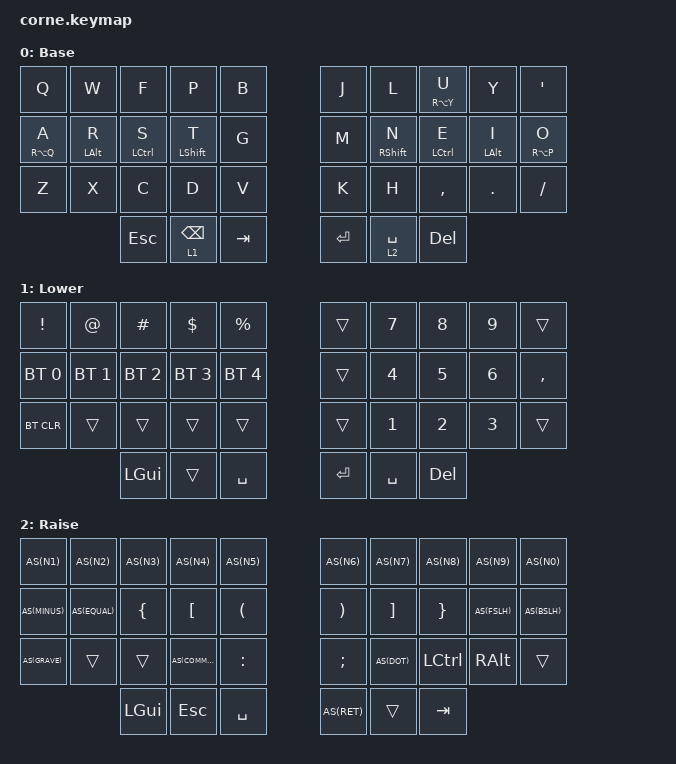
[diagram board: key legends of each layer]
/*
 * Copyright (c) 2020 The ZMK Contributors
 *
 * SPDX-License-Identifier: MIT
 */

#include <behaviors.dtsi>
#include <dt-bindings/zmk/keys.h>
#include <dt-bindings/zmk/bt.h>
#include <behaviors/unicode.dtsi>


#define AS(keycode) &as LS(keycode) keycode

/ {
    chosen {
        zmk,physical-layout = &foostan_corne_5col_layout;
    };

    behaviors {
        hml: home_row_mod_left {
            compatible = "zmk,behavior-hold-tap";
            #binding-cells = <2>;
            flavor = "balanced";
            require-prior-idle-ms = <150>;
            tapping-term-ms = <280>;
            quick-tap-ms = <175>;
            bindings = <&kp>, <&kp>;
            hold-trigger-key-positions = < 5 6 7 8 9 15 16 17 18 19 25 26 27 28 29 30 31 32 33 34 35>; // List of keys on the right side of the keyboard
            hold-trigger-on-release;
        };
        hmr: home_row_mod_right {
            compatible = "zmk,behavior-hold-tap";
            #binding-cells = <2>;
            flavor = "balanced";
            require-prior-idle-ms = <150>;
            tapping-term-ms = <280>;
            quick-tap-ms = <175>;
            bindings = <&kp>, <&kp>;
            hold-trigger-key-positions = < 0 1 2 3 4 10 11 12 13 14 20 21 22 23 24 30 31 32 33 34 35 >; // List of keys on the left side of the keyboard
            hold-trigger-on-release;
        };
        as: auto_shift {
            compatible = "zmk,behavior-hold-tap";
            #binding-cells = <2>;
            tapping_term_ms = <200>;
            quick_tap_ms = <0>;
            flavor = "tap-preferred";
            bindings = <&kp>, <&kp>;
        };
        umlaut: umlaut {
            compatible = "zmk,behavior-hold-tap";
            #binding-cells = <2>;
            flavor = "tap-preferred";
            tapping-term-ms = <250>;
            bindings = <&kp>, <&kp>;
        };
        
    };
        keymap {
                compatible = "zmk,keymap";

                default_layer {
// -----------------------------------------------------------------------------------------
// |  Q  |  W  |  E  |  R  |  T  |     |  Y  |  U   |  I   |  O   | P |
// |  A  |  S  |  D  |  F  |  G  |     |  H  |  J   |  K   |  L   | ' | 
// |  Z  |  X  |  C  |  V  |  B  |     |  N  |  M   | CTRL | META | . |
//             | GUI | LWR | SPC |     | ENT | RSE  | BSPC |
                        display-name = "Base";
                        bindings = <
   &kp Q &kp W &kp F  &kp P &kp B     &kp J   &kp L  &umlaut RA(Y) U     &kp Y     &kp SQT
   &umlaut RA(Q) A   &hml LALT R   &hml LCTRL S  &hml LSHFT T  &kp G  &kp M         &hmr RSHFT N  &hmr LCTRL E  &hmr LALT I   &umlaut RA(P) O 
   &kp Z &kp X &kp C &kp D &kp V     &kp K   &kp H  &kp COMMA  &kp DOT  &kp SLASH
        &kp ESC &lt 1 BSPC &kp TAB     &kp RET &lt 2 SPACE  &kp DEL
                        >;
                };

                lower_layer {
// -----------------------------------------------------------------------------------------
// | !     |  @  |  #  |  $  |  %  |     |  ^  |  &  |  *  |  (  |  )  |
// | BT1   | BT2 | BT3 | BT4 | BT5 |     | LFT | DWN |  UP | RGT |     |
// | BTCLR |     |     |     |     |     |     |     |     |     |     |
//               | GUI |     | SPC |     | ENT | ESC | TAB |
                        display-name = "Lower";
                        bindings = <
   &kp EXCL     &kp AT       &kp HASH     &kp DLLR     &kp PRCNT        &trans &kp N7  &kp N8 &kp N9  &trans
   &bt BT_SEL 0 &bt BT_SEL 1 &bt BT_SEL 2 &bt BT_SEL 3 &bt BT_SEL 4     &trans  &kp N4  &kp N5          &kp N6 &kp COMMA
   &bt BT_CLR   &trans       &trans       &trans       &trans           &trans    &kp N1    &kp N2      &kp N3    &trans 
                             &kp LGUI     &trans       &kp SPACE        &kp RET   &kp SPACE   &kp DEL
                        >;
                };

                raise_layer {
// -----------------------------------------------------------------------------------------
// | 1! |  2@ |  3# |  4$ |  5% |     |  6^ |  7& |  8* |  9(  |  0)  |
// | -_ |  =+ |  {  |  [  |  (  |     |  )  |  ]  |  }  |  /?  |  \|  |
// | `~ |     |     |  ,< |  :  |     |  ;  |  .> | CTRL| META |      |
//            | GUI | ESC | SPC |     | ENT |     | TAB |
                        display-name = "Raise";
                        bindings = <

   AS(N1)    AS(N2)    AS(N3)    AS(N4)    AS(N5)        AS(N6)    AS(N7)    AS(N8)    AS(N9)   AS(N0)
   AS(MINUS) AS(EQUAL) &kp LBRC  &kp LBKT  &kp LPAR      &kp RPAR  &kp RBKT  &kp RBRC  AS(FSLH) AS(BSLH)
   AS(GRAVE) &trans    &trans    AS(COMMA) &kp COLON     &kp SEMI  AS(DOT)   &kp LCTRL &kp RALT &trans
                       &kp LGUI  &kp ESC   &kp SPACE     AS(RET)   &trans    &kp TAB
                        >;
                };

                extra_1 {
                        status = "reserved";
                };

                extra_2 {
                        status = "reserved";
                };

                extra_3 {
                        status = "reserved";
                };
        };
};
